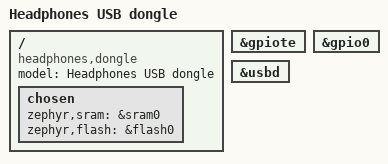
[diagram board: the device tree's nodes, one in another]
/dts-v1/;

#include <nordic/nrf52840_qiaa.dtsi>

/ {
    model = "Headphones USB dongle";
    compatible = "headphones,dongle";

    chosen {
        zephyr,sram = &sram0;
        zephyr,flash = &flash0;
    };
};

&gpiote {
    status = "okay";
};

&gpio0 {
    status = "okay";
};

zephyr_udc0: &usbd {
    status = "okay";
};
